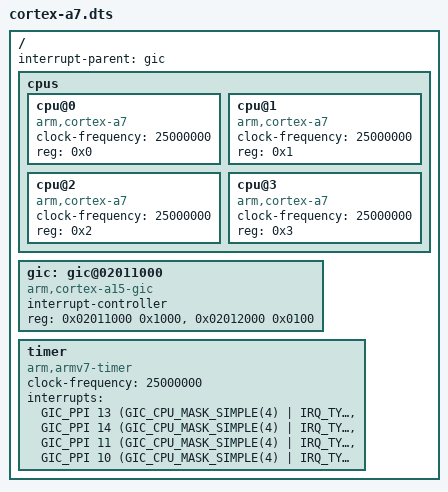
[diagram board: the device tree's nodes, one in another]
/*
 * Realtek Semiconductor Corp.
 *
 * Device Tree Structure
 *
 * Tony Wu (tonywu@realtek.com)
 */

/dts-v1/;

#include <dt-bindings/interrupt-controller/arm-gic.h>
#include "sheipa.dtsi"

/ {
	#address-cells = <1>;
	#size-cells = <1>;
	interrupt-parent = <&gic>;

	cpus {
		#address-cells = <1>;
		#size-cells = <0>;

		cpu@0 {
			device_type = "cpu";
			compatible = "arm,cortex-a7";
			clock-frequency = <25000000>;
			reg = <0x0>;
		};
		cpu@1 {
			device_type = "cpu";
			compatible = "arm,cortex-a7";
			clock-frequency = <25000000>;
			reg = <0x1>;
		};
		cpu@2 {
			device_type = "cpu";
			compatible = "arm,cortex-a7";
			clock-frequency = <25000000>;
			reg = <0x2>;
		};
		cpu@3 {
			device_type = "cpu";
			compatible = "arm,cortex-a7";
			clock-frequency = <25000000>;
			reg = <0x3>;
		};
	};

	gic: gic@02011000 {
		compatible = "arm,cortex-a15-gic";
		interrupt-controller;
		#interrupt-cells = <3>;
		reg = <0x02011000 0x1000>,
		      <0x02012000 0x0100>;
	};

	timer {
		compatible = "arm,armv7-timer";
		clock-frequency = <25000000>;
		interrupts = <GIC_PPI 13 (GIC_CPU_MASK_SIMPLE(4) | IRQ_TYPE_LEVEL_LOW)>,
			     <GIC_PPI 14 (GIC_CPU_MASK_SIMPLE(4) | IRQ_TYPE_LEVEL_LOW)>,
			     <GIC_PPI 11 (GIC_CPU_MASK_SIMPLE(4) | IRQ_TYPE_LEVEL_LOW)>,
			     <GIC_PPI 10 (GIC_CPU_MASK_SIMPLE(4) | IRQ_TYPE_LEVEL_LOW)>;
	};
};
